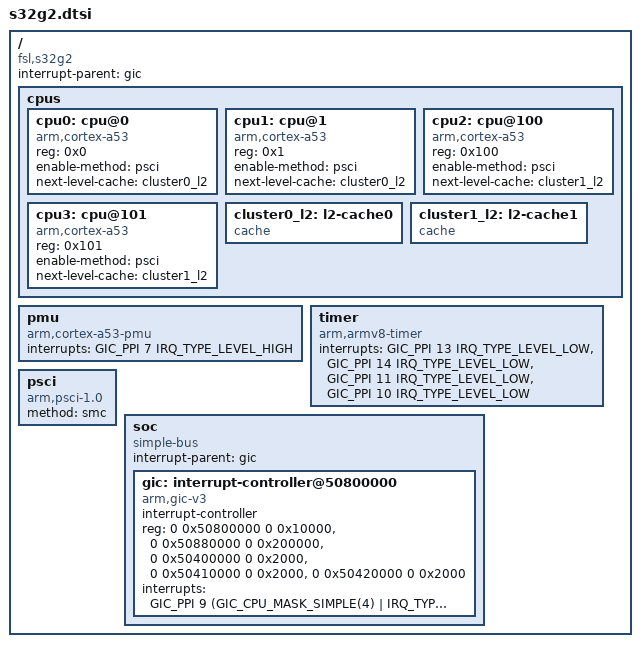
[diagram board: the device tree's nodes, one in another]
// SPDX-License-Identifier: GPL-2.0-or-later OR MIT
/*
 * Copyright (c) 2021 SUSE LLC
 */

#include <dt-bindings/interrupt-controller/arm-gic.h>

/ {
	compatible = "fsl,s32g2";
	interrupt-parent = <&gic>;
	#address-cells = <2>;
	#size-cells = <2>;

	cpus {
		#address-cells = <1>;
		#size-cells = <0>;

		cpu0: cpu@0 {
			device_type = "cpu";
			compatible = "arm,cortex-a53";
			reg = <0x0>;
			enable-method = "psci";
			next-level-cache = <&cluster0_l2>;
		};

		cpu1: cpu@1 {
			device_type = "cpu";
			compatible = "arm,cortex-a53";
			reg = <0x1>;
			enable-method = "psci";
			next-level-cache = <&cluster0_l2>;
		};

		cpu2: cpu@100 {
			device_type = "cpu";
			compatible = "arm,cortex-a53";
			reg = <0x100>;
			enable-method = "psci";
			next-level-cache = <&cluster1_l2>;
		};

		cpu3: cpu@101 {
			device_type = "cpu";
			compatible = "arm,cortex-a53";
			reg = <0x101>;
			enable-method = "psci";
			next-level-cache = <&cluster1_l2>;
		};

		cluster0_l2: l2-cache0 {
			compatible = "cache";
		};

		cluster1_l2: l2-cache1 {
			compatible = "cache";
		};
	};

	pmu {
		compatible = "arm,cortex-a53-pmu";
		interrupts = <GIC_PPI 7 IRQ_TYPE_LEVEL_HIGH>;
	};

	timer {
		compatible = "arm,armv8-timer";
		interrupts = <GIC_PPI 13 IRQ_TYPE_LEVEL_LOW>,
			     <GIC_PPI 14 IRQ_TYPE_LEVEL_LOW>,
			     <GIC_PPI 11 IRQ_TYPE_LEVEL_LOW>,
			     <GIC_PPI 10 IRQ_TYPE_LEVEL_LOW>;
	};

	psci {
		compatible = "arm,psci-1.0";
		method = "smc";
	};

	soc {
		compatible = "simple-bus";
		interrupt-parent = <&gic>;
		#address-cells = <2>;
		#size-cells = <2>;

		ranges;

		gic: interrupt-controller@50800000 {
			compatible = "arm,gic-v3";
			#interrupt-cells = <3>;
			interrupt-controller;
			reg = <0 0x50800000 0 0x10000>,
			      <0 0x50880000 0 0x200000>,
			      <0 0x50400000 0 0x2000>,
			      <0 0x50410000 0 0x2000>,
			      <0 0x50420000 0 0x2000>;
			interrupts = <GIC_PPI 9 (GIC_CPU_MASK_SIMPLE(4) |
						 IRQ_TYPE_LEVEL_HIGH)>;
		};
	};
};
